# slm32x030 register map
Vendor: Keil; File version: 1.0.1
CPU: CM0 r2p1, little endian, no MPU, no FPU, 4 interrupt priority bits
Registers are 32-bit, read-write, reset 0x0 unless marked. A register's access mark holds for its fields unless they carry their own. Offsets are from the block's base; [hi:lo] are bit positions.

## I2C1 — I2C interface
Base 0x40005400
Same registers: I2C2 0x40005800
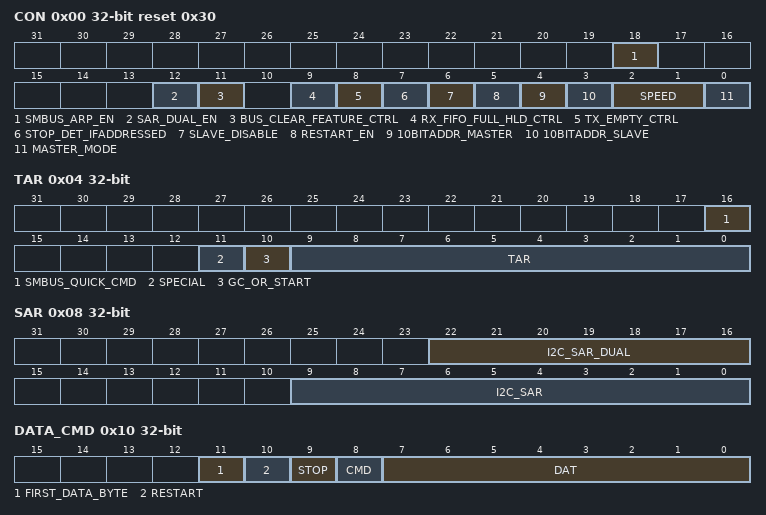
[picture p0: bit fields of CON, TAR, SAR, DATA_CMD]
0x00 CON access not given reset 0x30 — I2C_CON
  [18] SMBUS_ARP_EN — Later Add Description
  [12] SAR_DUAL_EN — Later Add Description
  [11] BUS_CLEAR_FEATURE_CTRL — Later Add Description
  [9] RX_FIFO_FULL_HLD_CTRL — Later Add Description
  [8] TX_EMPTY_CTRL — Later Add Description
  [7] STOP_DET_IFADDRESSED — Later Add Description
  [6] SLAVE_DISABLE — Later Add Description
  [5] RESTART_EN — Later Add Description
  [4] 10BITADDR_MASTER — Later Add Description
  [3] 10BITADDR_SLAVE — Later Add Description
  [2:1] SPEED — Later Add Description
  [0] MASTER_MODE — Later Add Description
0x04 TAR access not given — I2C_TAR
  [16] SMBUS_QUICK_CMD — Later Add Description
  [11] SPECIAL — Later Add Description
  [10] GC_OR_START — Later Add Description
  [9:0] TAR — Later Add Description
0x08 SAR access not given — I2C_SAR
  [22:16] I2C_SAR_DUAL — Later Add Description
  [9:0] I2C_SAR — Later Add Description
0x10 DATA_CMD access not given — I2C_DATA_CMD
  [11] FIRST_DATA_BYTE — Later Add Description
  [10] RESTART — Later Add Description
  [9] STOP — Later Add Description
  [8] CMD — Later Add Description
  [7:0] DAT — Later Add Description
0x14 SS_SCL_HCNT access not given — I2C_SS_SCL_HCNT
  [15:0] I2C_SS_SCL_HCNT — Later Add Description
0x18 SS_SCL_SCNT access not given — I2C_SS_SCL_SCNT
  [15:0] I2C_SS_SCL_LCNT — Later Add Description
0x1C FS_SCL_HCNT access not given — I2C_FS_SCL_HCNT
  [15:0] I2C_FS_SCL_HCNT — Later Add Description
0x20 FS_SCL_LCNT access not given — I2C_FS_SCL_LCNT
  [15:0] I2C_FS_SCL_LCNT — Later Add Description
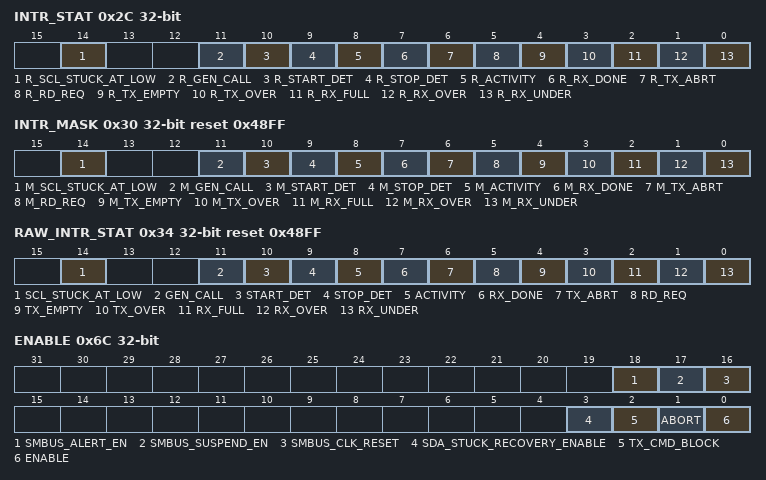
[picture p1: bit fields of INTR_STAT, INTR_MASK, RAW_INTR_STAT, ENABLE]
0x2C INTR_STAT access per field — I2C_INTR_STAT
  [14] R_SCL_STUCK_AT_LOW ro — Later Add Description
  [11] R_GEN_CALL rw — Later Add Description
  [10] R_START_DET rw — Later Add Description
  [9] R_STOP_DET rw — Later Add Description
  [8] R_ACTIVITY rw — Later Add Description
  [7] R_RX_DONE rw — Later Add Description
  [6] R_TX_ABRT rw — Later Add Description
  [5] R_RD_REQ rw — Later Add Description
  [4] R_TX_EMPTY rw — Later Add Description
  [3] R_TX_OVER rw — Later Add Description
  [2] R_RX_FULL rw — Later Add Description
  [1] R_RX_OVER rw — Later Add Description
  [0] R_RX_UNDER rw — Later Add Description
0x30 INTR_MASK reset 0x48FF — I2C_INTR_MASK
  [14] M_SCL_STUCK_AT_LOW — Later Add Description
  [11] M_GEN_CALL — Later Add Description
  [10] M_START_DET — Later Add Description
  [9] M_STOP_DET — Later Add Description
  [8] M_ACTIVITY — Later Add Description
  [7] M_RX_DONE — Later Add Description
  [6] M_TX_ABRT — Later Add Description
  [5] M_RD_REQ — Later Add Description
  [4] M_TX_EMPTY — Later Add Description
  [3] M_TX_OVER — Later Add Description
  [2] M_RX_FULL — Later Add Description
  [1] M_RX_OVER — Later Add Description
  [0] M_RX_UNDER — Later Add Description
0x34 RAW_INTR_STAT access not given reset 0x48FF — I2C_RAW_INTR_STAT
  [14] SCL_STUCK_AT_LOW — Later Add Description
  [11] GEN_CALL — Later Add Description
  [10] START_DET — Later Add Description
  [9] STOP_DET — Later Add Description
  [8] ACTIVITY — Later Add Description
  [7] RX_DONE — Later Add Description
  [6] TX_ABRT — Later Add Description
  [5] RD_REQ — Later Add Description
  [4] TX_EMPTY — Later Add Description
  [3] TX_OVER — Later Add Description
  [2] RX_FULL — Later Add Description
  [1] RX_OVER — Later Add Description
  [0] RX_UNDER — Later Add Description
0x38 RX_TL access not given — I2C_RX_TL
  [7:0] RX_TL — Later Add Description
0x3C TX_TL access not given — I2C_TX_TL
  [7:0] TX_TL — Later Add Description
0x40 CLR_INTR access not given — I2C_CLR_INTR
  [0] CLR_INTR — Later Add Description
0x44 CLR_RX_UNDER access not given — I2C_CLR_RX_UNDER
  [0] CLR_RX_UNDER — Later Add Description
0x48 CLR_RX_OVER access not given — I2C_CLR_RX_OVER
  [0] CLR_RX_OVER — Later Add Description
0x4C CLR_TX_OVER access not given — I2C_CLR_TX_OVER
  [0] CLR_TX_OVER — Later Add Description
0x50 CLR_RD_REQ access not given — I2C_CLR_RD_REQ
  [0] CLR_RD_REQ — Later Add Description
0x54 CLR_TX_ABRT access not given — I2C_CLR_TX_ABRT
  [0] CLR_TX_ABRT — Later Add Description
0x58 CLR_RX_DONE access not given — I2C_CLR_RX_DONE
  [0] CLR_RX_DONE — Later Add Description
0x5C CLR_ACTIVITY access not given — I2C_CLR_ACTIVITY
  [0] CLR_ACTIVITY — Later Add Description
0x60 CLR_STOP_DET access not given — I2C_CLR_STOP_DET
  [0] CLR_STOP_DET — Later Add Description
0x64 CLR_START_DET access not given — I2C_CLR_START_DET
  [0] CLR_START_DET — Later Add Description
0x68 CLR_GEN_CALL access not given — I2C_CLR_GEN_CALL
  [0] CLR_START_DET — Later Add Description
0x6C ENABLE access not given — I2C_ENABLE
  [18] SMBUS_ALERT_EN — Later Add Description
  [17] SMBUS_SUSPEND_EN — Later Add Description
  [16] SMBUS_CLK_RESET — Later Add Description
  [3] SDA_STUCK_RECOVERY_ENABLE — Later Add Description
  [2] TX_CMD_BLOCK — Later Add Description
  [1] ABORT — Later Add Description
  [0] ENABLE — Later Add Description
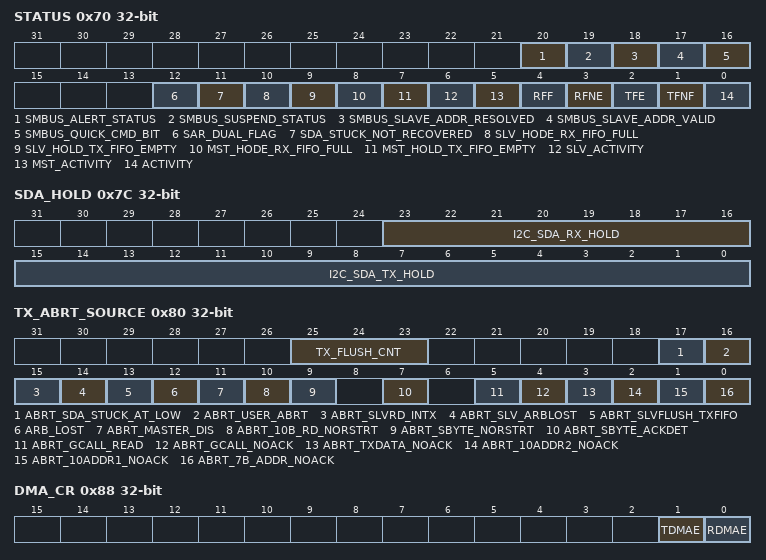
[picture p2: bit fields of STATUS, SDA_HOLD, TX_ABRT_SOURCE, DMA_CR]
0x70 STATUS access not given — I2C_STATUS
  [20] SMBUS_ALERT_STATUS — Later Add Description
  [19] SMBUS_SUSPEND_STATUS — Later Add Description
  [18] SMBUS_SLAVE_ADDR_RESOLVED — Later Add Description
  [17] SMBUS_SLAVE_ADDR_VALID — Later Add Description
  [16] SMBUS_QUICK_CMD_BIT — Later Add Description
  [12] SAR_DUAL_FLAG — Later Add Description
  [11] SDA_STUCK_NOT_RECOVERED — Later Add Description
  [10] SLV_HODE_RX_FIFO_FULL — Later Add Description
  [9] SLV_HOLD_TX_FIFO_EMPTY — Later Add Description
  [8] MST_HODE_RX_FIFO_FULL — Later Add Description
  [7] MST_HOLD_TX_FIFO_EMPTY — Later Add Description
  [6] SLV_ACTIVITY — Later Add Description
  [5] MST_ACTIVITY — Later Add Description
  [4] RFF — Later Add Description
  [3] RFNE — Later Add Description
  [2] TFE — Later Add Description
  [1] TFNF — Later Add Description
  [0] ACTIVITY — Later Add Description
0x74 TXFLR access not given — I2C_TXFLR
  [2:0] TXFLR — Later Add Description
0x78 RXFLR access not given — I2C_RXFLR
  [2:0] RXFLR — Later Add Description
0x7C SDA_HOLD access not given — I2C_SDA_HOLD
  [23:16] I2C_SDA_RX_HOLD — Later Add Description
  [15:0] I2C_SDA_TX_HOLD — Later Add Description
0x80 TX_ABRT_SOURCE access not given — I2C_TX_ABRT_SOURCE
  [25:23] TX_FLUSH_CNT — Later Add Description
  [17] ABRT_SDA_STUCK_AT_LOW — Later Add Description
  [16] ABRT_USER_ABRT — Later Add Description
  [15] ABRT_SLVRD_INTX — Later Add Description
  [14] ABRT_SLV_ARBLOST — Later Add Description
  [13] ABRT_SLVFLUSH_TXFIFO — Later Add Description
  [12] ARB_LOST — Later Add Description
  [11] ABRT_MASTER_DIS — Later Add Description
  [10] ABRT_10B_RD_NORSTRT — Later Add Description
  [9] ABRT_SBYTE_NORSTRT — Later Add Description
  [7] ABRT_SBYTE_ACKDET — Later Add Description
  [5] ABRT_GCALL_READ — Later Add Description
  [4] ABRT_GCALL_NOACK — Later Add Description
  [3] ABRT_TXDATA_NOACK — Later Add Description
  [2] ABRT_10ADDR2_NOACK — Later Add Description
  [1] ABRT_10ADDR1_NOACK — Later Add Description
  [0] ABRT_7B_ADDR_NOACK — Later Add Description
0x88 DMA_CR access not given — I2C_DMA_CR
  [1] TDMAE — Later Add Description
  [0] RDMAE — Later Add Description
0x8C DMA_TDLR access not given — I2C_DMA_TDLR
  [2:0] DMATDL — Later Add Description
0x90 DMA_RDLR access not given — I2C_DMA_RDLR
  [2:0] DMARDL — Later Add Description
0x94 SDA_SETUP access not given — I2C_SDA_SETUP
  [7:0] SDA_SETUP — Later Add Description
0x98 ACK_GENERAL_CALL access not given — I2C_ACK_GENERAL_CALL
  [0] ACK_GEN_CALL — Later Add Description
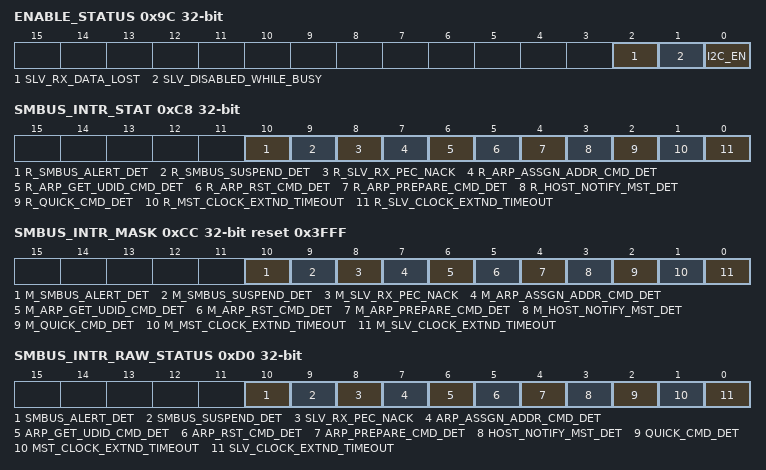
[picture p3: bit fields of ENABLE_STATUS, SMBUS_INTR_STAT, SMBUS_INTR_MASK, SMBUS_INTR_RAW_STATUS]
0x9C ENABLE_STATUS access not given — I2C_ENABLE_STATUS
  [2] SLV_RX_DATA_LOST — Later Add Description
  [1] SLV_DISABLED_WHILE_BUSY — Later Add Description
  [0] I2C_EN — Later Add Description
0xA0 FS_SPKLEN access not given — I2C_FS_SPKLEN
  [7:0] I2C_FS_SPKLEN — Later Add Description
0xAC SCL_STUCK_AT_LOW_TIMEOUT access not given — I2C_SCL_STUCK_AT_LOW_TIMEOUT
  [31:0] I2C_SCL_STUCK_AT_LOW_TIMEOUT — Later Add Description
0xB0 SDA_STUCK_AT_LOW_TIMEOUT access not given — I2C_SDA_STUCK_AT_LOW_TIMEOUT
  [31:0] I2C_SDA_STUCK_AT_LOW_TIMEOUT — Later Add Description
0xB4 CLR_SCL_STUCK_DET access not given — I2C_CLR_SCL_STUCK_DET
  [0] CLR_SCL_STUCK — Later Add Description
0xBC SMBUS_CLK_LOW_SEXT_TIMEOUT access not given — I2C_SMBUS_CLK_LOW_SEXT_TIMEOUT
  [31:0] SMBUS_CLK_LOW_SEXT_TIMEOUT — Later Add Description
0xC0 SMBUS_CLK_LOW_MEXT_TIMEOUT access not given — I2C_SMBUS_CLK_LOW_MEXT_TIMEOUT
  [31:0] SMBUS_CLK_LOW_MEXT_TIMEOUT — Later Add Description
0xC4 SMBUS_THIGH_MAX_IDLE_COUNT access not given — I2C_SMBUS_THIGH_MAX_IDLE_COUNT
  [15:0] SMBUS_THIGH_MAX_IDLE_COUNT — Later Add Description
0xC8 SMBUS_INTR_STAT access not given — I2C_SMBUS_INTR_STAT
  [10] R_SMBUS_ALERT_DET — Later Add Description
  [9] R_SMBUS_SUSPEND_DET — Later Add Description
  [8] R_SLV_RX_PEC_NACK — Later Add Description
  [7] R_ARP_ASSGN_ADDR_CMD_DET — Later Add Description
  [6] R_ARP_GET_UDID_CMD_DET — Later Add Description
  [5] R_ARP_RST_CMD_DET — Later Add Description
  [4] R_ARP_PREPARE_CMD_DET — Later Add Description
  [3] R_HOST_NOTIFY_MST_DET — Later Add Description
  [2] R_QUICK_CMD_DET — Later Add Description
  [1] R_MST_CLOCK_EXTND_TIMEOUT — Later Add Description
  [0] R_SLV_CLOCK_EXTND_TIMEOUT — Later Add Description
0xCC SMBUS_INTR_MASK access not given reset 0x3FFF — I2C_SMBUS_INTR_MASK
  [10] M_SMBUS_ALERT_DET — Later Add Description
  [9] M_SMBUS_SUSPEND_DET — Later Add Description
  [8] M_SLV_RX_PEC_NACK — Later Add Description
  [7] M_ARP_ASSGN_ADDR_CMD_DET — Later Add Description
  [6] M_ARP_GET_UDID_CMD_DET — Later Add Description
  [5] M_ARP_RST_CMD_DET — Later Add Description
  [4] M_ARP_PREPARE_CMD_DET — Later Add Description
  [3] M_HOST_NOTIFY_MST_DET — Later Add Description
  [2] M_QUICK_CMD_DET — Later Add Description
  [1] M_MST_CLOCK_EXTND_TIMEOUT — Later Add Description
  [0] M_SLV_CLOCK_EXTND_TIMEOUT — Later Add Description
0xD0 SMBUS_INTR_RAW_STATUS access not given — I2C_SMBUS_INTR_RAW_STATUS
  [10] SMBUS_ALERT_DET — Later Add Description
  [9] SMBUS_SUSPEND_DET — Later Add Description
  [8] SLV_RX_PEC_NACK — Later Add Description
  [7] ARP_ASSGN_ADDR_CMD_DET — Later Add Description
  [6] ARP_GET_UDID_CMD_DET — Later Add Description
  [5] ARP_RST_CMD_DET — Later Add Description
  [4] ARP_PREPARE_CMD_DET — Later Add Description
  [3] HOST_NOTIFY_MST_DET — Later Add Description
  [2] QUICK_CMD_DET — Later Add Description
  [1] MST_CLOCK_EXTND_TIMEOUT — Later Add Description
  [0] SLV_CLOCK_EXTND_TIMEOUT — Later Add Description
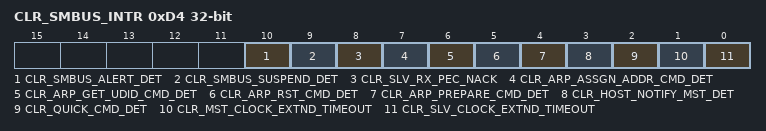
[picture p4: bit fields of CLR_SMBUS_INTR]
0xD4 CLR_SMBUS_INTR access not given — I2C_CLR_SMBUS_INTR
  [10] CLR_SMBUS_ALERT_DET — Later Add Description
  [9] CLR_SMBUS_SUSPEND_DET — Later Add Description
  [8] CLR_SLV_RX_PEC_NACK — Later Add Description
  [7] CLR_ARP_ASSGN_ADDR_CMD_DET — Later Add Description
  [6] CLR_ARP_GET_UDID_CMD_DET — Later Add Description
  [5] CLR_ARP_RST_CMD_DET — Later Add Description
  [4] CLR_ARP_PREPARE_CMD_DET — Later Add Description
  [3] CLR_HOST_NOTIFY_MST_DET — Later Add Description
  [2] CLR_QUICK_CMD_DET — Later Add Description
  [1] CLR_MST_CLOCK_EXTND_TIMEOUT — Later Add Description
  [0] CLR_SLV_CLOCK_EXTND_TIMEOUT — Later Add Description
0xD8 SAR_OPT access not given — I2C_SAR_OPT
  [7:0] Sar_opt — Later Add Description
0xDC SMBUS_UDID access not given — I2C_SMBUS_UDID
  [31:0] SMBUS_UDID — Later Add Description
